AUTOSAR XML (schema 00050)
package /ComponentTypes
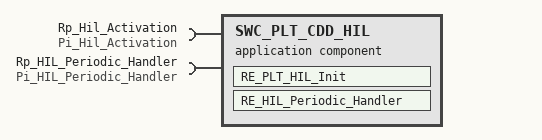
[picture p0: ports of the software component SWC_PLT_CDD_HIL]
  application sw component type SWC_PLT_CDD_HIL
    require port Rp_Hil_Activation: nonqueued-receiver-com-spec{data-element=De_Hil_Activation, filter=data-filter-type=ALWAYS, init-value=0}, required-interface=Pi_Hil_Activation
    require port Rp_HIL_Periodic_Handler: required-interface=Pi_HIL_Periodic_Handler
    behavior SWC_PLT_CDD_HIL_InternalBehavior: handle-termination-and-restart=NO-SUPPORT
      init event SWC_PLT_CDD_HIL_InitEvent: start-on-event=RE_PLT_HIL_Init
      external trigger occurred event EXTO_RE_HIL_Periodic_Handler_Rp_HIL_Periodic_Handler_Trigger: start-on-event=RE_HIL_Periodic_Handler, trigger=Rp_HIL_Periodic_Handler.Trigger
      runnable RE_PLT_HIL_Init
        data-receive-point-by-arguments:
          access REC_Rp_Hil_Activation_De_Hil_Activation: accessed-variable=Rp_Hil_Activation.De_Hil_Activation
      runnable RE_HIL_Periodic_Handler
  swc implementation SWC_PLT_CDD_HIL_Implementation: behavior=SWC_PLT_CDD_HIL_InternalBehavior
    resource consumption ResourceConsumption
      5 x memory section, all with sw-addrmethod=CODE:
        CODE
        VAR_SAVED_ZONE
        VAR_NOINIT_UNSPECIFIED
        VAR_INIT_UNSPECIFIED
        VAR_ZERO_INIT_UNSPECIFIED
